VERSION ""

NS_ :

BS_:

BU_:

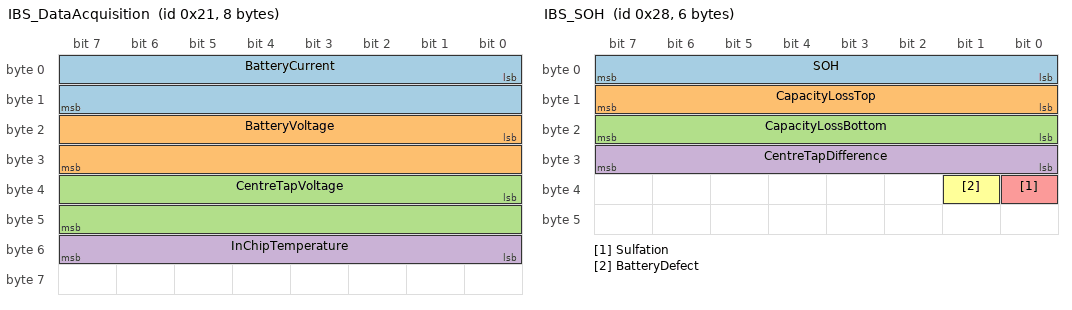
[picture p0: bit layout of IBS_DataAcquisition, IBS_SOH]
BO_ 33 IBS_DataAcquisition: 8 Vector__XXX
 SG_ BatteryCurrent : 0|16@1+ (0.001,-32.766) [-20|19.999] "A" Vector__XXX
 SG_ BatteryVoltage : 16|16@1+ (0.001,0) [0|32] "V" Vector__XXX
 SG_ CentreTapVoltage : 32|16@1+ (0.001,0) [0|32] "" Vector__XXX
 SG_ InChipTemperature : 48|8@1+ (0.5,-40) [0|215] "degC" Vector__XXX

BO_ 34 IBS_SOC: 6 Vector__XXX
 SG_ SOC : 0|16@1+ (0.1,0) [0|150] "%" Vector__XXX
 SG_ BatteryTemperature : 32|8@1+ (1,-40) [0|0] "degC" Vector__XXX

BO_ 40 IBS_SOH: 6 Vector__XXX
 SG_ SOH : 0|8@1+ (0.5,0) [0|100] "%" Vector__XXX
 SG_ CapacityLossTop : 8|8@1+ (0.5,0) [0|100] "%" Vector__XXX
 SG_ CapacityLossBottom : 16|8@1+ (0.5,0) [0|100] "%" Vector__XXX
 SG_ CentreTapDifference : 24|8@1+ (0.5,-127) [-127|127] "%" Vector__XXX
 SG_ Sulfation : 32|1@1+ (1,0) [0|0] "" Vector__XXX
 SG_ BatteryDefect : 33|1@1+ (1,0) [0|0] "" Vector__XXX

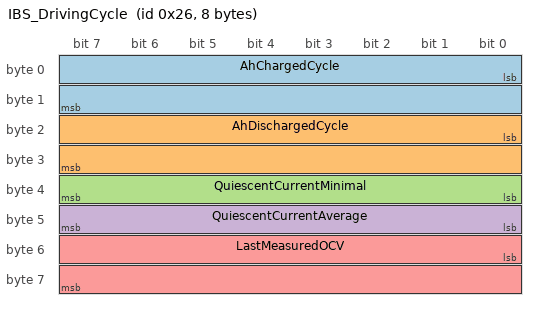
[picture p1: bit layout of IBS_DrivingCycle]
BO_ 38 IBS_DrivingCycle: 8 Vector__XXX
 SG_ AhChargedCycle : 0|16@1+ (0.01,0) [0|0] "Ah" Vector__XXX
 SG_ AhDischargedCycle : 16|16@1+ (0.01,0) [0|0] "Ah" Vector__XXX
 SG_ QuiescentCurrentMinimal : 32|8@1+ (0.002,0) [0|0] "A" Vector__XXX
 SG_ QuiescentCurrentAverage : 40|8@1+ (0.002,0) [0|0] "A" Vector__XXX
 SG_ LastMeasuredOCV : 48|16@1+ (1,0) [0|0] "mV" Vector__XXX

BA_DEF_  "BusType" STRING ;
BA_DEF_  "ProtocolType" STRING ;
BA_DEF_DEF_  "BusType" "";
BA_DEF_DEF_  "ProtocolType" "";
BA_ "BusType" "LIN";
